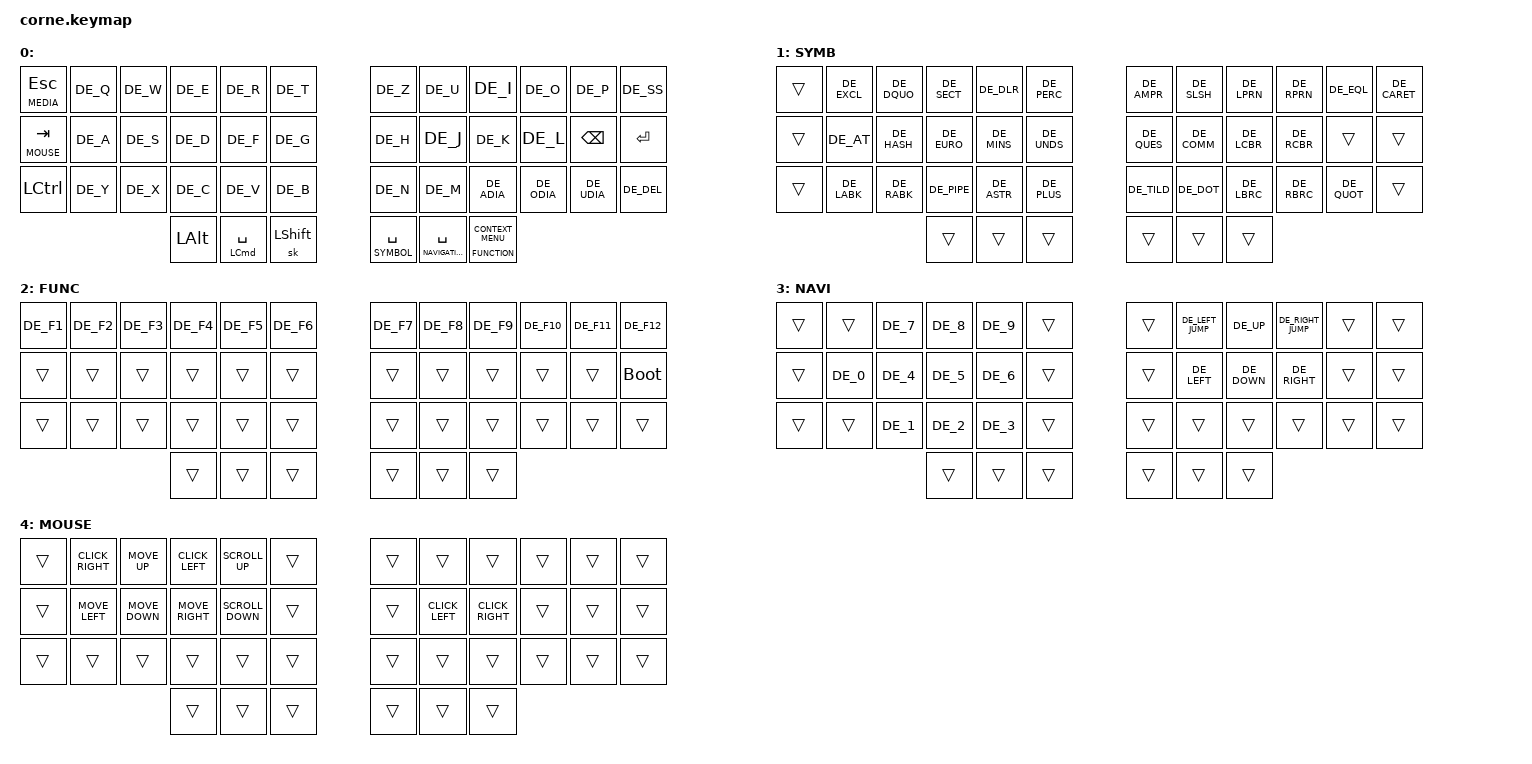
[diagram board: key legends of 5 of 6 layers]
/*
 * Copyright (c) 2020 The ZMK Contributors
 *
 * SPDX-License-Identifier: MIT
 */

#include <behaviors.dtsi>
#include <dt-bindings/zmk/keys.h>
#include <dt-bindings/zmk/bt.h>
#include <dt-bindings/zmk/outputs.h>
#include <dt-bindings/zmk/ext_power.h>
#include <dt-bindings/led/led.h>
#include <dt-bindings/zmk/backlight.h>
#include <dt-bindings/zmk/rgb.h>
#include <dt-bindings/zmk/reset.h>
#include "keymap_german_mac_iso_zmk.h"
#include "keypos_42keys.h"
#include "config_zmk.h"
#include "mouse.dtsi"

/ {
    keymap {
        compatible = "zmk,keymap";

        default_layer {
            // -----------------------------------------------------------------------------------------
            // |  TAB |  Q  |  W  |  E  |  R  |  T  |   |  Y  |  U   |  I  |  O  |  P  | BKSP |
            // | CTRL |  A  |  S  |  D  |  F  |  G  |   |  H  |  J   |  K  |  L  |  ;  |  '   |
            // | SHFT |  Z  |  X  |  C  |  V  |  B  |   |  N  |  M   |  ,  |  .  |  /  | ESC  |
            //                    | GUI | LWR | SPC |   | ENT | RSE  | ALT |
        label = "";
            bindings = <
&lt MEDIA ESC     DE_Q  DE_W  DE_E          DE_R                    DE_T            DE_Z              DE_U                  DE_I                         DE_O     DE_P           DE_SS
&lt MOUSE TAB     DE_A  DE_S  DE_D          DE_F                    DE_G            DE_H              DE_J                  DE_K                         DE_L     &kp BACKSPACE  &kp ENTER
&kp LEFT_CONTROL  DE_Y  DE_X  DE_C          DE_V                    DE_B            DE_N              DE_M                  DE_ADIA                      DE_ODIA  DE_UDIA        DE_DEL        
                              &kp LEFT_ALT  &mt LEFT_COMMAND SPACE  &sk LEFT_SHIFT  &lt SYMBOL SPACE  &lt NAVIGATION SPACE  &lt FUNCTION K_CONTEXT_MENU
            >;
        };

        lower_layer {
            // -----------------------------------------------------------------------------------------
            // |  TAB |  1  |  2  |  3  |  4  |  5  |   |  6  |  7  |  8  |  9  |  0  | BKSP |
            // | BTCLR| BT1 | BT2 | BT3 | BT4 | BT5 |   | LFT | DWN |  UP | RGT |     |      |
            // | SHFT |     |     |     |     |     |   |     |     |     |     |     |      |
            //                    | GUI |     | SPC |   | ENT |     | ALT |
        label = "SYMB";
            bindings = <
&trans  DE_EXCL  DE_DQUO  DE_SECT  DE_DLR   DE_PERC  DE_AMPR  DE_SLSH  DE_LPRN  DE_RPRN  DE_EQL   DE_CARET
&trans  DE_AT    DE_HASH  DE_EURO  DE_MINS  DE_UNDS  DE_QUES  DE_COMM  DE_LCBR  DE_RCBR  &trans   &trans
&trans  DE_LABK  DE_RABK  DE_PIPE  DE_ASTR  DE_PLUS  DE_TILD  DE_DOT   DE_LBRC  DE_RBRC  DE_QUOT  &trans
                          &trans   &trans   &trans   &trans   &trans   &trans
            >;
        };

        raise_layer {
            // -----------------------------------------------------------------------------------------
            // |  TAB |  !  |  @  |  #  |  $  |  %  |   |  ^  |  &  |  *  |  (  |  )  | BKSP |
            // | CTRL |     |     |     |     |     |   |  -  |  =  |  [  |  ]  |  \  |  `   |
            // | SHFT |     |     |     |     |     |   |  _  |  +  |  {  |  }  | "|" |  ~   |
            //                    | GUI |     | SPC |   | ENT |     | ALT |

        label = "FUNC";
            bindings = <
DE_F1   DE_F2   DE_F3   DE_F4   DE_F5   DE_F6   DE_F7   DE_F8   DE_F9   DE_F10   DE_F11   DE_F12
&trans  &trans  &trans  &trans  &trans  &trans  &trans  &trans  &trans  &trans   &trans   &bootloader
&trans  &trans  &trans  &trans  &trans  &trans  &trans  &trans  &trans  &trans   &trans   &trans
                        &trans  &trans  &trans  &trans  &trans  &trans
            >;
        };

        Navigation {
        label = "NAVI";
            bindings = <
&trans  &trans  DE_7  DE_8    DE_9    &trans    &trans  DE_LEFT_JUMP  DE_UP    DE_RIGHT_JUMP  &trans  &trans
&trans  DE_0    DE_4  DE_5    DE_6    &trans    &trans  DE_LEFT       DE_DOWN  DE_RIGHT       &trans  &trans
&trans  &trans  DE_1  DE_2    DE_3    &trans    &trans  &trans        &trans   &trans         &trans  &trans
                      &trans  &trans  &trans    &trans  &trans        &trans
            >;
        };

        mouse_layer {
        label = "MOUSE";
         bindings = <
&trans  CLICK_RIGHT  MOVE_UP    CLICK_LEFT  SCROLL_UP    &trans  &trans     &trans      &trans       &trans     &trans   &trans
&trans  MOVE_LEFT    MOVE_DOWN  MOVE_RIGHT  SCROLL_DOWN  &trans  &trans     CLICK_LEFT  CLICK_RIGHT  &trans     &trans   &trans
&trans  &trans       &trans     &trans      &trans       &trans  &trans     &trans      &trans       &trans     &trans   &trans
                                &trans      &trans       &trans  &trans     &trans      &trans
            >;
        };

        media_layer {
        label = "MEDIA";
         bindings = <
&trans  &trans  &trans  &trans  &trans  &bootloader  DE_BRI_DN  DE_BRI_UP  DE_VOL_DN  DE_VOL_UP  DE_MUTE  &trans
&trans  &trans  &trans  &trans  &trans  &bt BT_CLR   &trans     &trans     &trans     &trans     &trans   &trans
&trans  &bt BT(0)    &bt BT(1)  &bt BT(2)   &bt BT(3)    &bt BT(4)    &trans     &trans     &trans     &trans     &trans   &trans
                                &trans      &trans       &trans       &trans     &trans     &trans
            >;
        };

// }}}

    };
};


// MARCOS CONFIG

// /* ========================================
// FileName: corne.keymap
// Date: 15:17 23.September.2022
// Author: Marcos Chow Castro
// Email: mctechnology170318@gmail.com
// GitHub: https://github.com/mctechnology17
// Brief: keymap for the wireless corne keyboard
//                              ╔═╦═╦═╗
//                       ╔════╗ ║║║║║╔╝
//                       ║╔╗╔╗║ ║║║║║╚╗
//                       ╚╝║║╚╝ ║╠═╩╩═╝
//                         ║╠═╦═╣╚╦═╦╦═╦╗╔═╦═╦╦╗
//                         ║║╩╣═╣║║║║║╬║╚╣╬║╬║║║
//                         ╚╩═╩═╩╩╩╩═╩═╩═╩═╬╗╠╗║
//                                         ╚═╩═╝
// Copyright (c) 2020 The ZMK Contributors
// SPDX-License-Identifier: MIT
// ========================================= */
// // ### include {{{
// #include <behaviors.dtsi>
// #include <dt-bindings/zmk/keys.h>
// #include <dt-bindings/zmk/bt.h>
// #include <dt-bindings/zmk/outputs.h>
// #include <dt-bindings/zmk/ext_power.h>
// #include <dt-bindings/led/led.h>
// #include <dt-bindings/zmk/backlight.h>
// #include <dt-bindings/zmk/rgb.h>
// #include <dt-bindings/zmk/reset.h>
// #include "keymap_german_mac_iso_zmk.h"
// #include "keypos_42keys.h"
// #include "config_zmk.h"
// #include "mouse.dtsi"
// &led_strip {
//     chain-length = <27>;
// };
// // }}}
// / {
// // ### macros {{{
//    macros {
//       #include "macros.dtsi"
//    };
// // }}}
// // ### combos {{{
//    combos {
//       compatible = "zmk,combos";

//       unlock {
//          bindings = <&to DEFAULT>;
//          key-positions = <LT5 LH0 RH0 RT5>;
//          layers = <LOCK>;
//       };

//       lock {
//          bindings = <&to LOCK>;
//          key-positions = <LT5 RH0>;
//          layers = <LX_>;
//       };
//    };
// // }}}
//    // ### conditional_layers {{{
//    conditional_layers {
//         compatible = "zmk,conditional-layers";

//         tri_layer {
//             if-layers = <SYMBOL FUNCTION>;
//             then-layer = <LX_>;
//         };
//     };

//    //}}}
//    keymap {
//       compatible = "zmk,keymap";
//       // ### default_layer {{{
//       default_layer {
//       /*.------------------------------------------------.                         .-------------------------------------------------.
//          |LT4 ESC |   Q   |   W   |   E   |   R   |   T   |                         |   Z   |   U   |   I   |   O   |   P   | BACKSPC |
//          |--------+-------+-------+-------+-------+-------|                         |-------+-------+-------+-------+-------+---------|
//          |LT5 TAB |   A   |   S   |   D   |   F   |   G   |                         |   H   |   J   |   K   |   L   |  UP   |   ENTER |
//          |--------+-------+-------+-------+-------+-------|                         |-------+-------+-------+-------+-------+---------|
//          |SHIFT   |   Y   |   X   |   C   |   V   |   B   |                         |   N   |   M   |LSFT , |  LEFT |  DOWN |   RIGHT |
//          '---------------------------------------------------------|       |----------------------------------------------------------'
//                                   |  CTRL    |  CMD       |   ALT  |       | LT1 SPACE | LT2 CMD   | LT3 RALT |
//                                   '--------------------------------'       '----------------------------------'*/
//          label = "Marcos";
//          bindings = <
//             MEDIA_ESC   DE_Q   DE_W   DE_E   DE_R      DE_T                            DE_Z        DE_U  DE_I         DE_O     DE_P     DE_BSPC
//             MOUSE_TAB   DE_A   DE_S   DE_D   DE_F      DE_G                            DE_H        DE_J  DE_K         DE_L     DE_UP    DE_RET
//             DE_LSHFT    DE_Y   DE_X   DE_C   DE_V      DE_B                            DE_N        DE_M  LSHFT_COMMA  DE_LEFT  DE_DOWN  DE_RIGHT
//                                              DE_LCTRL  DE_LGUI  DE_RALT  NUMBER_SPACE  SYMBOL_RGUI  FUNCTION_RALT
//             >;
//       };
//       // }}}
//       // ### number_layer {{{
//       number_layer {
//        /*.-------------------------------------------------.                         .-------------------------------------------------.
//          |   0     |   1   |   2   |   3   |   -   |   +   |                         |   ß   |   Ü   |   Ä   |   Ö   |   Ñ   |BACKSPC  |
//          |---------+-------+-------+-------+-------+-------|                         |-------+-------+-------+-------+-------+---------|
//          |CAPS_LOCK|   4   |   5   |   6   |   /   |   *   |                         |   #   |   ~   |   ?   |   @   |  UP   |   ENTER |
//          |---------+-------+-------+-------+-------+-------|                         |-------+-------+-------+-------+-------+---------|
//          | SHIFT   |   7   |   8   |   9   |   %   |   =   |                         |   .   |   ´   |   `   |  LEFT |  DOWN |   RIGHT |
//          '----------------------------------------------------------|       |----------------------------------------------------------'
//                                    |  CTRL |  CMD  |     SPACE      |       |        |  LSFT |      ALTGR    |
//                                    '--------------------------------'       '--------------------------------'*/
//          label = "NUMBER";
//          bindings = <
//          DE_0      DE_1   DE_2   DE_3    DE_MINS   DE_PLUS                     DE_SS    DE_UDIA  DE_ADIA    DE_ODIA  &ene_small DE_BSPC
//          DE_CAPS   DE_4   DE_5   DE_6    DE_SLSH   DE_ASTR                     DE_HASH  DE_TILD  DE_QUES    DE_AT    DE_UP      DE_RET
//          DE_LSHFT  DE_7   DE_8   DE_9    DE_PERC   DE_EQL                      DE_DOT   DE_ACUT  DE_GRV     DE_LEFT  DE_DOWN    DE_RIGHT
//                                          DE_LCTRL  DE_LGUI    DE_SPACE   XXX   DE_LSHFT DE_RALT
//             >;
//       };
//       // }}}
//       // ### symbol_layer {{{
//       symbol_layer {
//        /*.------------------------------------------------.          TODO:          .-------------------------------------------------.
//          |   $    |   (   |   )   |   [   |   ]   |   &   |                         |  `    |   '   |   ´   |   "   |       |BACKSPC  |
//          |--------+-------+-------+-------+-------+-------|                         |-------+-------+-------+-------+-------+---------|
//          |   %    |   {   |   }   |   ^   |PAGE_UP|   #   |                         |   \   |   |   |   /   |  &    |  UP   |   ENTER |
//          |--------+-------+-------+-------+-------+-------|                         |-------+-------+-------+-------+-------+---------|
//          |SHIFT   |    <  |   >   |  HOME |PAGE_DO|  END  |                         |   ~   |   '   |       |  LEFT |  DOWN |   RIGHT |
//          '---------------------------------------------------------|       |----------------------------------------------------------'
//                                   |  CTRL    |  CMD       | SPACE  |       |  ENTER | ALTGR |          CTRL |
//                                   '--------------------------------'       '--------------------------------'*/
//          label = "SYMBOL";
//          bindings = <
//          DE_DLR   DE_LPRN  DE_RPRN   DE_LBRC  DE_RBRC    DE_AMPR                    DE_GRV   DE_QUOT   DE_ACUT  DE_LN_DQUO  XXX      DE_BSPC
//          DE_PERC  DE_LCBR  DE_RCBR   DE_CARET DE_PG_UP   DE_HASH                    DE_BSLS  DE_PIPE   DE_SLSH  DE_AMPR     DE_UP    DE_RET
//          DE_LSHFT DE_LABK  DE_RABK   DE_HOME  DE_PG_DN   DE_END                     DE_TILD  DE_QUOT   XXX      DE_LEFT     DE_DOWN  DE_RIGHT
//                                               DE_LCTRL   DE_LGUI  DE_SPACE  DE_RET  SYMBOL_RGUI  FUNCTION_RALT
//          >;
//       };
//       // }}}
//       // ### function_layer {{{
//       function_layer {
//        /*.------------------------------------------------.                         .-------------------------------------------------.
//          |    F1  |  F2   |   F3  |   F4  | SPELL |TRADUCT|                         |DE_F13 | DE_F14|DE_F15 | DE_F16| BRI_DN| BRI_UP  |
//          |--------+-------+-------+-------+-------+-------|                         |-------+-------+-------+-------+-------+---------|
//          |    F5  |  F6   |   F7  |    F8 |   \   |ALFRED |                         |C-A-DEL|DE_F19 |DE_F20 |CLR_LIN|PAGE_UP|         |
//          |--------+-------+-------+-------+-------+-------|                         |-------+-------+-------+-------+-------+---------|
//          |    F9  |   F10 |   F11 |   F12 |ALFRED |EMOJI  |                         |L_SHIFT|L_SHIFT|R_SHIFT|  HOME |PAGE_DO|    END  |
//          '----------------------------------------------------------|       |----------------------------------------------------------'
//                                    |  CTRL    |  CMD       |   ALT  |       |  TAB   |   ´   |          CTRL |
//                                    '--------------------------------'       '--------------------------------'
//          LCTL(LGUI(KC_D)), LCTL(LGUI(KC_SPC))*/
//          label = "FUNCTION";
//          bindings = <
//          DE_F1  DE_F2   DE_F3   DE_F4    SPELL    TRADUCT                   &macro6   &macro5   &macro8    &macro2   DE_BRI_DN  DE_BRI_UP
//          DE_F5  DE_F6   DE_F7   DE_F8    DE_BSLS  SNIPPET                   TASKM     &macro1   &macro3    &macro4   DE_PG_UP   &macro9
//          DE_F9  DE_F10  DE_F11  DE_F12   CLIPBRD  EMOJI                     DE_LSHFT  DE_LSHFT  DE_RSHFT   DE_HOME   DE_PG_DN   DE_END
//                                          DE_LCTRL DE_LGUI  DE_LALT  DE_TAB  DE_ACUT   DE_LCTRL
//                               >;
//                       };
//       // }}}
//       // ### media_layer {{{
//       media_layer {
//        /*.------------------------------------------------.                         .-------------------------------------------------.
//          |        |SC_FLOW|TXTSNIP|SC_SHOT|OP_TERM|       |                         |POS1   |POS2   |LANG_1 |LANG_2 | STOP  |  DELETE |
//          |--------+-------+-------+-------+-------+-------|                         |-------+-------+-------+-------+-------+---------|
//          |bootlder|SC_SPSF|SC_RE  |       |       |       |                         |POS3   |POS4   |LANG_3 |SHUFFLE|VOL_UP |PLAY/PAUS|
//          |--------+-------+-------+-------+-------+-------|                         |-------+-------+-------+-------+-------+---------|
//          |reset   |       |       |       |       |       |                         |       |       |  MUTE |  PREV |VOL_DOW|  NEXT   |
//          '---------------------------------------------------------|       |----------------------------------------------------------'
//                                   |  CTRL    |  CMD       |   ALT  |       |  SPACE | ALTGR |          CTRL |
//                                   '--------------------------------'       '--------------------------------'*/
//          label = "MEDIA";
//          bindings = <
//          XXX          SC_FLOW  TXTSNIP  SC_SHOT OP_TERM   XXX               POS1        POS2      DE_LANG1   DE_LANG2    DE_STOP    DE_DEL
//          &bootloader  SC_SPSF  SC_RE    XXX     XXX       XXX               POS3        POS4      DE_LANG3   DE_SHUFFLE  DE_VOL_UP  DE_PLAY
//          &sys_reset   XXX      XXX      XXX     XXX       XXX               &ene_small  &ene_big  DE_MUTE    DE_PREV     DE_VOL_DN  DE_NEXT
//                                         DE_LCTRL  DE_LGUI  DE_LALT  DE_SPACE  DE_RALT DE_LCTRL
//                               >;
//                       };
//       // }}}
//       // ### mouse_layer: mouse {{{
//       mouse_layer {
//        /*.------------------------------------------------.                         .-------------------------------------------------.
//          |WH_LEFT |WH_RIGH|       |OUT_USB|OUT_BLE|OUT_TOG|                         | BRD-  | BRI+  |  SPD- | SPI+  |WH_DOWN| WH_UP   |
//          |--------+-------+-------+-------+-------+-------|                         |-------+-------+-------+-------+-------+---------|
//          |        |CLICK_1|CLICK_2|CLICK_3|BT_PRV | BT_NXT|                         | HUD-  | HUI+  |       |CLICK_1| UP    |CLICK_2  |
//          |--------+-------+-------+-------+-------+-------|                         |-------+-------+-------+-------+-------+---------|
//          |BT_CLR  |BT_0   |BT_1   |BT_2   |BT_3   |BT_4   |                         | SAD-  | SAI+  | RESET | LEFT  | DOWN  | RIGHT   |
//          '---------------------------------------------------------|       |----------------------------------------------------------'
//                                   |EP_OFF  | EP_ON|         EP_TOG |       | EFF-  | EFR+   |   RGB_TOG     |
//                                   '--------------------------------'       '--------------------------------'*/
//          label = "MOUSE";
//          bindings = <
//          SCROLL_LEFT SCROLL_RIGHT XXX         &out OUT_USB &out OUT_BLE  &out OUT_TOG             &rgb_ug RGB_BRD &rgb_ug RGB_BRI &rgb_ug RGB_SPD                    &rgb_ug RGB_SPI SCROLL_DOWN SCROLL_UP
//          XXX         CLICK_LEFT   CLICK_RIGHT CLICK_MIDDLE &bt BT_PRV    &bt BT_NXT               &rgb_ug RGB_HUD &rgb_ug RGB_HUI &rgb_ug RGB_COLOR_HSB(0,0,100)     CLICK_LEFT      MOVE_UP     CLICK_RIGHT
//          &bt BT_CLR  &bt BT(0)    &bt BT(1)   &bt BT(2)    &bt BT(3)     &bt BT(4)                &rgb_ug RGB_SAD &rgb_ug RGB_SAI &rgb_ug RGB_COLOR_HSB(224,100,100) MOVE_LEFT       MOVE_DOWN   MOVE_RIGHT
//                                  &ext_power EP_OFF    &ext_power EP_ON   &ext_power EP_TOG    &rgb_ug RGB_EFF &rgb_ug RGB_EFR &rgb_ug RGB_TOG
//                               >;
//                       };
//       // }}}
//       // ### linux_symbol {{{
//       linux_symbol {
//        /*.------------------------------------------------.          TODO:          .-------------------------------------------------.
//          |   $    |   (   |   )   |   [   |   ]   |   &   |                         |  `    |   '   |   ´   |bootldr| reset |BACKSPC  |
//          |--------+-------+-------+-------+-------+-------|                         |-------+-------+-------+-------+-------+---------|
//          |   %    |   {   |   }   |   ^   |PAGE_UP|   #   |                         |    \  |   |   |   /   |   &   |  UP   |   ENTER |
//          |--------+-------+-------+-------+-------+-------|                         |-------+-------+-------+-------+-------+---------|
//          |SHIFT   |    <  |   >   |  HOME |PAGE_DO|  END  |                         |   ~   |   '   |   @   |  LEFT |  DOWN |   RIGHT |
//          '---------------------------------------------------------|       |----------------------------------------------------------'
//          DE_LN_DQUO               |DE_F13 |    DE_F14     | DE_F15 |       |  SPACE | ALTGR |          CTRL |
//                                   '--------------------------------'       '--------------------------------'*/
//          label = "LX_";
//          bindings = <
//          DE_DLR   DE_LN_LPRN  DE_LN_RPRN   DE_LN_LBRC  DE_LN_RBRC  DE_LN_AMPS                DE_GRV      DE_QUOT     DE_ACUT     &bootloader &sys_reset  DE_BSPC
//          DE_PERC  DE_LN_LCBR  DE_LN_RCBR   DE_LN_CARET DE_PG_UP    DE_HASH                   DE_LN_BSLH  DE_LN_PIPE  DE_LN_FSLH  DE_LN_AMPS  DE_UP       DE_RET
//          DE_LSHFT DE_LN_LABK  DE_LN_RABK   DE_HOME     DE_PG_DN    DE_END                    DE_LN_TILDE DE_QUOT     DE_LN_AT    NAV_LEFT    DE_DOWN     NAV_RIGHT
//                                               &macro7   &macro5  &macro8  DE_SPACE  DE_RALT  DE_LCTRL
//          >;
//       };
//       // }}}
//    // ### lock  {{{
//       lock {
//          label = "Lock";
//          bindings = <
//             &none  &none  &none  &none  &none  &none  &none  &none  &none  &none  &none  &none
//             &none  &none  &none  &none  &none  &none  &none  &none  &none  &none  &none  &none
//             &none  &none  &none  &none  &none  &none  &none  &none  &none  &none  &none  &none
//                                  &none  &none  &none  &none  &none  &none
//             >;
//         };
//    //}}}
//    };
// };

// // vim: filetype=dts fdm=marker:
